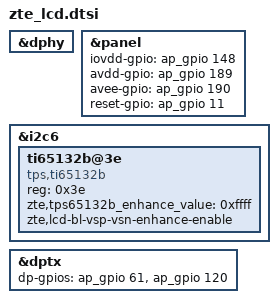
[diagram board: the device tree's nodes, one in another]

&dphy {
	/delete-property/ sprd,ulps-disabled;
};

&panel {
	iovdd-gpio = <&ap_gpio 148 GPIO_ACTIVE_HIGH>;
	avdd-gpio = <&ap_gpio 189 GPIO_ACTIVE_HIGH>;
	avee-gpio = <&ap_gpio 190 GPIO_ACTIVE_HIGH>;
	reset-gpio = <&ap_gpio 11 GPIO_ACTIVE_HIGH>;
};

&i2c6 {
	status = "okay";
	ti65132b@3e {
		compatible = "tps,ti65132b";
		reg = <0x3e>;
		/*if set tps65132b_enhance_value,means bigger than this board_id*/
		zte,tps65132b_enhance_value = <0xffff>;
		zte,lcd-bl-vsp-vsn-enhance-enable;
	};
};

&dptx {
	status = "okay";
	dp-gpios = <&ap_gpio 61 GPIO_ACTIVE_HIGH>,
			<&ap_gpio 120 GPIO_ACTIVE_HIGH>;

};
